# MK20DZ10 register map
Vendor: Freescale Semiconductor, Inc.; Series: Kinetis_K; File version: 1.6
CPU: CM4 r0p1, little endian, no MPU, no FPU, VTOR, 4 interrupt priority bits
Registers are 32-bit, read-write, reset 0x0 unless marked. A register's access mark holds for its fields unless they carry their own. Offsets are from the block's base; [hi:lo] are bit positions; {n}, {i} and the like mark numbered series; 'fields as' and 'values as' point back to an identical list.

## SysTick — System timer
Base 0xE000E010; register names take the prefix SYST_
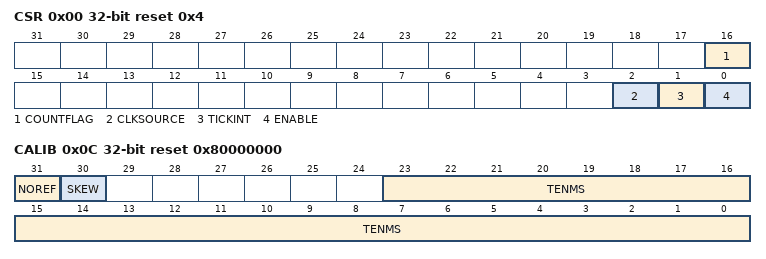
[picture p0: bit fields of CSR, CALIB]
0x00 CSR reset 0x4 — SysTick Control and Status Register
  [16] COUNTFLAG
  [2] CLKSOURCE
    0=external clock; 1=processor clock
  [1] TICKINT
    0=counting down to 0 does not assert the SysTick exception request; 1=counting down to 0 asserts the SysTick exception request
  [0] ENABLE
    0=counter disabled; 1=counter enabled
0x04 RVR — SysTick Reload Value Register
  [23:0] RELOAD — Value to load into the SysTick Current Value Register when the counter reaches 0
0x08 CVR — SysTick Current Value Register
  [23:0] CURRENT — Current value at the time the register is accessed
0x0C CALIB ro reset 0x80000000 — SysTick Calibration Value Register
  [31] NOREF
    0=The reference clock is provided; 1=The reference clock is not provided
  [30] SKEW
    0=10ms calibration value is exact; 1=10ms calibration value is inexact, because of the clock frequency
  [23:0] TENMS — Reload value to use for 10ms timing

## NVIC — Nested Vectored Interrupt Controller
Base 0xE000E100
{0x0+4i} NVICISER{i} (i=0..3) — Interrupt Set Enable Register n
  [31:0] SETENA — Interrupt set enable bits
{0x80+4i} NVICICER{i} (i=0..3) — Interrupt Clear Enable Register n
  [31:0] CLRENA — Interrupt clear-enable bits
{0x100+4i} NVICISPR{i} (i=0..3) — Interrupt Set Pending Register n
  [31:0] SETPEND — Interrupt set-pending bits
{0x180+4i} NVICICPR{i} (i=0..3) — Interrupt Clear Pending Register n
  [31:0] CLRPEND — Interrupt clear-pending bits
{0x200+4i} NVICIABR{i} (i=0..3) — Interrupt Active bit Register n
  [31:0] ACTIVE — Interrupt active flags
{0x300+i} NVICIP{i} 8-bit (i=0..105) — Interrupt Priority Register n
  [7:0] PRI{i} — Priority of interrupt {i}
0xE00 NVICSTIR — Software Trigger Interrupt Register
  [8:0] INTID — Interrupt ID of the interrupt to trigger, in the range 0-239. For example, a value of 0x03 specifies interrupt IRQ3.

## MCM — Core Platform Miscellaneous Control Module
Base 0xE0080000; register names take the prefix MCM_
0x08 PLASC 16-bit ro reset 0x1F — Crossbar switch (AXBS) slave configuration
  [7:0] ASC — Each bit in the ASC field indicates if there is a corresponding connection to the crossbar switch's slave input port.
    0=A bus slave connection to AXBS input port n is absent; 1=A bus slave connection to AXBS input port n is present
0x0A PLAMC 16-bit ro reset 0x3F — Crossbar switch (AXBS) master configuration
  [7:0] AMC — Each bit in the AMC field indicates if there is a corresponding connection to the AXBS master input port.
    0=A bus master connection to AXBS input port n is absent; 1=A bus master connection to AXBS input port n is present
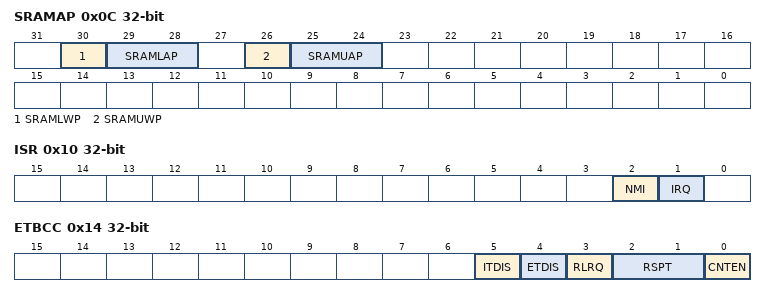
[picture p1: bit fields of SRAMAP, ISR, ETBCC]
0x0C SRAMAP — SRAM arbitration and protection
  [30] SRAMLWP — SRAM_L write protect
  [29:28] SRAMLAP — SRAM_L arbitration priority
    0=Round robin; 1=Special round robin (favors SRAM backoor accesses over the processor); 2=Fixed priority. Processor has highest, backdoor has lowest; 3=Fixed priority. Backdoor has highest, processor has lowest
  [26] SRAMUWP — SRAM_U write protect
  [25:24] SRAMUAP — SRAM_U arbitration priority
    values as SRAMLAP
0x10 ISR — Interrupt status register
  [2] NMI — Non-maskable interrupt pending
    0=No pending NMI; 1=Due to the ETB counter expiring, an NMI is pending
  [1] IRQ — Normal interrupt pending
    0=No pending interrupt; 1=Due to the ETB counter expiring, a normal interrupt is pending
0x14 ETBCC — ETB counter control register
  [5] ITDIS — ITM-to-TPIU disable
    0=ITM-to-TPIU trace path enabled; 1=ITM-to-TPIU trace path disabled
  [4] ETDIS — ETM-to-TPIU disable
    0=ETM-to-TPIU trace path enabled; 1=ETM-to-TPIU trace path disabled
  [3] RLRQ — Reload request
    0=No effect; 1=Clears pending debug halt, NMI, or IRQ interrupt requests
  [2:1] RSPT — Response type
    0=No response when the ETB count expires; 1=Generate a normal interrupt when the ETB count expires; 2=Generate an NMI when the ETB count expires; 3=Generate a debug halt when the ETB count expires
  [0] CNTEN — Counter enable
    0=ETB counter disabled; 1=ETB counter enabled
0x18 ETBRL — ETB reload register
  [10:0] RELOAD — Byte count reload value
0x1C ETBCNT ro — ETB counter value register
  [10:0] COUNTER — Byte count counter value
